AUTOSAR XML (schema 00046)
package /ComponentTypes
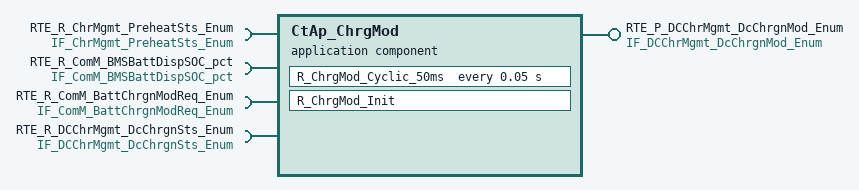
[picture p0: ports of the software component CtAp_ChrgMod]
  application sw component type CtAp_ChrgMod
    provide port RTE_P_DCChrMgmt_DcChrgnMod_Enum: nonqueued-sender-com-spec{data-element=tec_DCChrMgmt_DcChrgnMod_Enum, init-value=0}, provided-interface=IF_DCChrMgmt_DcChrgnMod_Enum
    4 x require port:
      RTE_R_ChrMgmt_PreheatSts_Enum: nonqueued-receiver-com-spec{data-element=tec_ChrMgmt_PreheatSts_Enum, filter=data-filter-type=ALWAYS, init-value=0}, required-interface=IF_ChrMgmt_PreheatSts_Enum
      RTE_R_ComM_BMSBattDispSOC_pct: nonqueued-receiver-com-spec{data-element=tec_ComM_BMSBattDispSOC_pct, filter=data-filter-type=ALWAYS, init-value=0}, required-interface=IF_ComM_BMSBattDispSOC_pct
      RTE_R_ComM_BattChrgnModReq_Enum: nonqueued-receiver-com-spec{data-element=tec_ComM_BattChrgnModReq_Enum, filter=data-filter-type=ALWAYS, init-value=0}, required-interface=IF_ComM_BattChrgnModReq_Enum
      RTE_R_DCChrMgmt_DcChrgnSts_Enum: nonqueued-receiver-com-spec{data-element=tec_DCChrMgmt_DcChrgnSts_Enum, filter=data-filter-type=ALWAYS, init-value=0}, required-interface=IF_DCChrMgmt_DcChrgnSts_Enum
    behavior CtAp_ChrgMod_InternalBehavior
      timing event TMT_R_ChrgMod_Cyclic_50ms: start-on-event=R_ChrgMod_Cyclic_50ms, period=0.05
      init event CtAp_ChrgMod_InitEvent: start-on-event=R_ChrgMod_Init
      runnable R_ChrgMod_Cyclic_50ms
        data-receive-point-by-arguments:
          4 x access:
            REC_RTE_R_ChrMgmt_PreheatSts_Enum_tec_ChrMgmt_PreheatSts_Enum: accessed-variable=RTE_R_ChrMgmt_PreheatSts_Enum.tec_ChrMgmt_PreheatSts_Enum
            REC_RTE_R_ComM_BMSBattDispSOC_pct_tec_ComM_BMSBattDispSOC_pct: accessed-variable=RTE_R_ComM_BMSBattDispSOC_pct.tec_ComM_BMSBattDispSOC_pct
            REC_RTE_R_ComM_BattChrgnModReq_Enum_tec_ComM_BattChrgnModReq_Enum: accessed-variable=RTE_R_ComM_BattChrgnModReq_Enum.tec_ComM_BattChrgnModReq_Enum
            REC_RTE_R_DCChrMgmt_DcChrgnSts_Enum_tec_DCChrMgmt_DcChrgnSts_Enum: accessed-variable=RTE_R_DCChrMgmt_DcChrgnSts_Enum.tec_DCChrMgmt_DcChrgnSts_Enum
        data-send-points:
          access SEND_RTE_P_DCChrMgmt_DcChrgnMod_Enum_tec_DCChrMgmt_DcChrgnMod_Enum: accessed-variable=RTE_P_DCChrMgmt_DcChrgnMod_Enum.tec_DCChrMgmt_DcChrgnMod_Enum
      runnable R_ChrgMod_Init
  swc implementation CtAp_ChrgMod_Implementation: behavior=CtAp_ChrgMod_InternalBehavior
